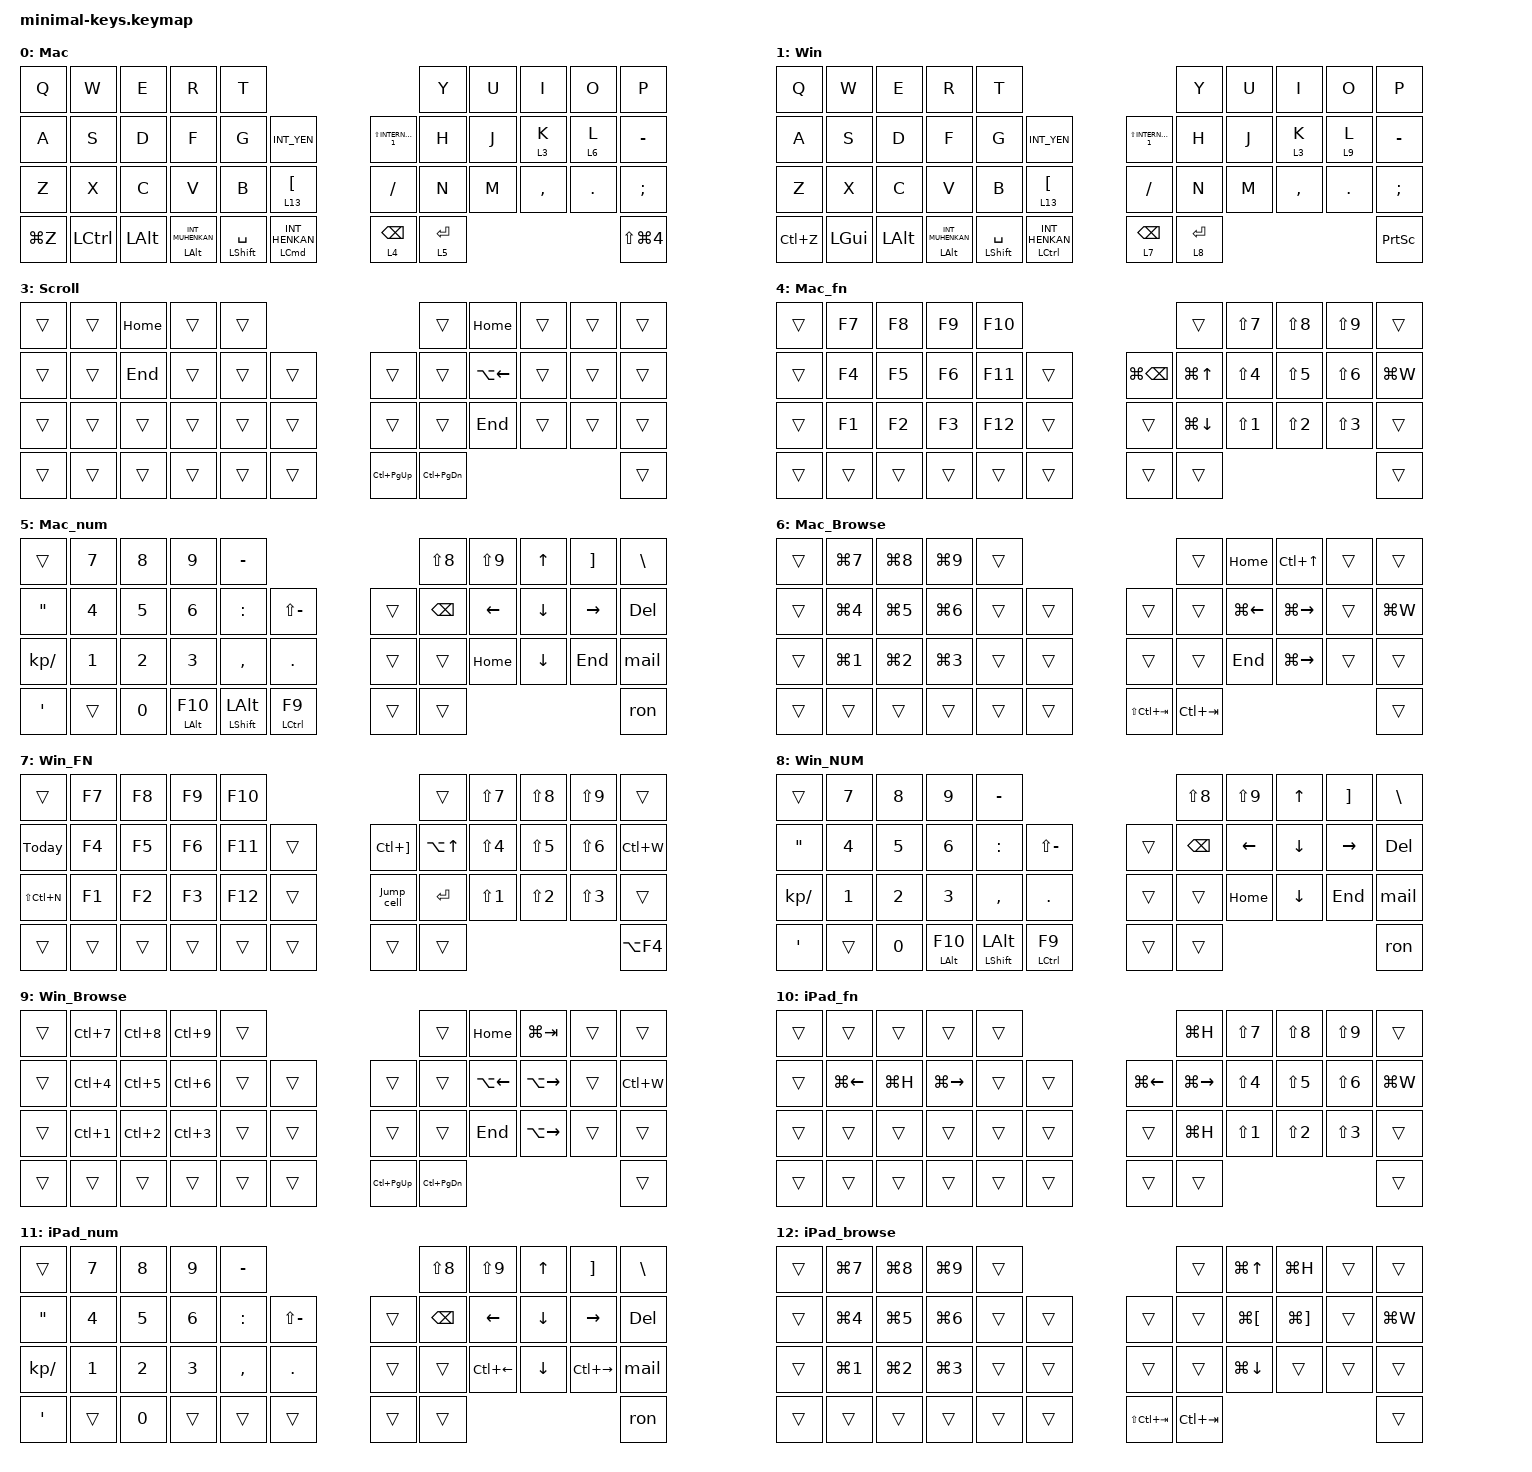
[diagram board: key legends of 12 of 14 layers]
#include <behaviors.dtsi>
#include <dt-bindings/zmk/bt.h>
#include <dt-bindings/zmk/keys.h>
#include <dt-bindings/zmk/pointing.h>

#undef ZMK_POINTING_DEFAULT_SCRL_VAL

#define ZMK_POINTING_DEFAULT_SCRL_VAL 100
#define MOUSE 6

&mt {
    flavor = "balanced";
    quick-tap-ms = <0>;
};

/ {
    combos {
        compatible = "zmk,combos";

        tab {
            bindings = <&kp TAB>;
            key-positions = <23 22>;
        };

        eq {
            bindings = <&kp LS(MINUS)>;
            key-positions = <20 21>;
        };

        question {
            bindings = <&kp QUESTION>;
            key-positions = <32 33>;
        };

        L_click {
            bindings = <&mkp LCLK>;
            key-positions = <18 19>;
        };

        R_click {
            bindings = <&mkp RCLK>;
            key-positions = <19 20>;
        };

        Escape {
            bindings = <&kp ESCAPE>;
            key-positions = <1 2>;
        };

        Mac_copy {
            bindings = <&kp LG(C)>;
            key-positions = <24 26>;
            layers = <0 5 7 6 2 10 11 12>;
        };

        Mac_Paste {
            bindings = <&kp LG(V)>;
            key-positions = <24 25>;
            layers = <0 5 7 6 10 11 2 12>;
        };

        Mac_Cut {
            bindings = <&kp LG(X)>;
            key-positions = <23 24>;
            layers = <0 5 6 2 4 10 11 12>;
        };

        L_click2 {
            bindings = <&mkp LCLK>;
            key-positions = <30 31>;
        };

        R_click2 {
            bindings = <&mkp RCLK>;
            key-positions = <31 32>;
        };

        Win_copy {
            bindings = <&kp LC(C)>;
            key-positions = <24 26>;
            layers = <1 7 8 9>;
        };

        Win_Cut {
            bindings = <&kp LC(X)>;
            key-positions = <24 23>;
            layers = <1 7 8 9>;
        };

        Win_Paste {
            bindings = <&kp LC(V)>;
            key-positions = <24 25>;
            layers = <1 8 7 9>;
        };
    };

    macros {
        to_layer_0: to_layer_0 {
            compatible = "zmk,behavior-macro-one-param";
            #binding-cells = <1>;
            bindings = <&to 0 &macro_param_1to1 &kp MACRO_PLACEHOLDER>;
            label = "TO_LAYER_0";
        };

        Jump_cell: Jump_cell {
            compatible = "zmk,behavior-macro";
            #binding-cells = <0>;
            bindings = <&kp F5>, <&macro_wait_time 20>, <&kp ENTER>;

            label = "JUMP_CELL";
        };

        Today: Today {
            compatible = "zmk,behavior-macro";
            #binding-cells = <0>;
            bindings =
                <&kp LS(LC(D))>,
                <&macro_wait_time 20>,
                <&kp LEFT_SHIFT &kp LCTRL>,
                <&macro_wait_time 20>,
                <&kp LEFT_SHIFT &kp LCTRL>,
                <&macro_wait_time 30>;

            label = "TODAY";
        };

        sw_Mac: sw_Mac {
            compatible = "zmk,behavior-macro";
            #binding-cells = <0>;
            bindings =
                <&bt BT_SEL 0>,
                <&macro_wait_time 500>,
                <&tog_off 1>,
                <&macro_wait_time 200>,
                <&tog_off 2>,
                <&macro_wait_time 200>;

            label = "SW_MAC";
        };

        sw_Win: sw_Win {
            compatible = "zmk,behavior-macro";
            #binding-cells = <0>;
            bindings =
                <&bt BT_SEL 1>,
                <&macro_wait_time 500>,
                <&tog_off 1>,
                <&macro_wait_time 200>,
                <&tog_off 2>,
                <&macro_wait_time 200>,
                <&tog_on 1>;

            label = "SW_WIN";
        };

        sw_iPad: sw_iPad {
            compatible = "zmk,behavior-macro";
            #binding-cells = <0>;
            bindings =
                <&bt BT_SEL 2>,
                <&macro_wait_time 500>,
                <&tog_off 1>,
                <&macro_wait_time 200>,
                <&tog_off 2>,
                <&macro_wait_time 200>,
                <&tog_on 2>;

            label = "SW_IPAD";
        };

        ron: ron {
            compatible = "zmk,behavior-macro";
            #binding-cells = <0>;
            bindings = <&kp R &kp O &kp N &kp B &kp A &kp K &kp U &kp R &kp O &kp N &kp B &kp A &kp K &kp U &kp N2 &kp N6 &kp LEFT_BRACKET &kp RET>;
            label = "RON";
        };

        mail: mail {
            compatible = "zmk,behavior-macro";
            #binding-cells = <0>;
            bindings = <&kp Y &kp U &kp K &kp I &kp DOT &kp M &kp O &kp R &kp I &kp T &kp A &kp N &kp I &kp LEFT_BRACKET &kp P &kp W &kp C &kp DOT &kp C &kp O &kp M &kp TAB>;
            label = "MAIL";
            wait-ms = <20>;
        };
    };

    behaviors {
        lt_to_layer_0: lt_to_layer_0 {
            compatible = "zmk,behavior-hold-tap";
            label = "LAYER_TAP_TO_0";
            bindings = <&mo>, <&to_layer_0>;

            #binding-cells = <2>;
            tapping-term-ms = <200>;
        };

        scroll_up_down: behavior_sensor_rotate_mouse_wheel_up_down {
            compatible = "zmk,behavior-sensor-rotate";
            #sensor-binding-cells = <0>;
            bindings = <&msc SCRL_UP>, <&msc SCRL_DOWN>;

            tap-ms = <20>;
        };

        scroll: scroll {
            compatible = "zmk,behavior-sensor-rotate";
            label = "SCROLL";
            #sensor-binding-cells = <0>;
            bindings = <&msc SCRL_DOWN>, <&msc SCRL_UP>;
        };

        tog_on: toggle_layer_on_only {
            compatible = "zmk,behavior-toggle-layer";
            #binding-cells = <1>;
        };

        tog_off: toggle_layer_off_only {
            compatible = "zmk,behavior-toggle-layer";
            #binding-cells = <1>;
            toggle-mode = "off";
        };
    };

    keymap {
        compatible = "zmk,keymap";

        Mac {
            bindings = <
&kp Q      &kp W      &kp E         &kp R                      &kp T                                                                         &kp Y        &kp U  &kp I      &kp O    &kp P
&kp A      &kp S      &kp D         &kp F                      &kp G                 &kp INT_YEN                    &kp LS(INTERNATIONAL_1)  &kp H        &kp J  &lt 3 K    &lt 6 L  &kp MINUS
&kp Z      &kp X      &kp C         &kp V                      &kp B                 &lt 13 LEFT_BRACKET            &kp SLASH                &kp N        &kp M  &kp COMMA  &kp DOT  &kp SEMICOLON
&kp LG(Z)  &kp LCTRL  &kp LEFT_ALT  &mt LEFT_ALT INT_MUHENKAN  &mt LEFT_SHIFT SPACE  &mt LEFT_COMMAND INT_HENKAN    &lt 4 BACKSPACE          &lt 5 ENTER                             &kp LS(LG(NUMBER_4))
            >;

            sensor-bindings = <&scroll_up_down>;
        };

        Win {
            bindings = <
&kp Q      &kp W         &kp E         &kp R                      &kp T                                                                  &kp Y        &kp U  &kp I      &kp O    &kp P
&kp A      &kp S         &kp D         &kp F                      &kp G                 &kp INT_YEN             &kp LS(INTERNATIONAL_1)  &kp H        &kp J  &lt 3 K    &lt 9 L  &kp MINUS
&kp Z      &kp X         &kp C         &kp V                      &kp B                 &lt 13 LEFT_BRACKET     &kp SLASH                &kp N        &kp M  &kp COMMA  &kp DOT  &kp SEMICOLON
&kp LC(Z)  &kp LEFT_GUI  &kp LEFT_ALT  &mt LEFT_ALT INT_MUHENKAN  &mt LEFT_SHIFT SPACE  &mt LCTRL INT_HENKAN    &lt 7 BACKSPACE          &lt 8 ENTER                             &kp PRINTSCREEN
            >;

            sensor-bindings = <&scroll_up_down>;
        };

        iPad {
            bindings = <
&kp Q      &kp W                                 &kp E         &kp R                  &kp T                                                                 &kp Y         &kp U  &kp I      &kp O     &kp P
&kp A      &kp S                                 &kp D         &kp F                  &kp G                 &kp INTERNATIONAL_3    &kp LS(INTERNATIONAL_1)  &kp H         &kp J  &lt 3 K    &lt 12 L  &kp MINUS
&kp Z      &kp X                                 &kp C         &kp V                  &kp B                 &lt 13 LEFT_BRACKET    &kp SLASH                &kp N         &kp M  &kp COMMA  &kp DOT   &kp SEMICOLON
&kp LG(Z)  &kp C_AC_NEXT_KEYBOARD_LAYOUT_SELECT  &kp LEFT_ALT  &mt (LCTRL) LC(SPACE)  &mt LEFT_SHIFT SPACE  &kp LEFT_COMMAND       &lt 10 BACKSPACE         &lt 11 ENTER                              &kp LS(LG(NUMBER_4))
            >;

            sensor-bindings = <&scroll_up_down>;
        };

        Scroll {
            bindings = <
&trans  &trans  &kp HOME  &trans  &trans                             &trans             &kp HOME            &trans  &trans  &trans
&trans  &trans  &kp END   &trans  &trans  &trans    &trans           &trans             &kp LA(LEFT_ARROW)  &trans  &trans  &trans
&trans  &trans  &trans    &trans  &trans  &trans    &trans           &trans             &kp END             &trans  &trans  &trans
&trans  &trans  &trans    &trans  &trans  &trans    &kp LC(PAGE_UP)  &kp LC(PAGE_DOWN)                                      &trans
            >;

            sensor-bindings = <&scroll_up_down>;
        };

        Mac_fn {
            bindings = <
&trans  &kp F7  &kp F8  &kp F9  &kp F10                               &trans              &kp LS(N7)  &kp LS(N8)  &kp LS(N9)  &trans
&trans  &kp F4  &kp F5  &kp F6  &kp F11  &trans    &kp LG(BACKSPACE)  &kp LG(UP_ARROW)    &kp LS(N4)  &kp LS(N5)  &kp LS(N6)  &kp LG(W)
&trans  &kp F1  &kp F2  &kp F3  &kp F12  &trans    &trans             &kp LG(DOWN_ARROW)  &kp LS(N1)  &kp LS(N2)  &kp LS(N3)  &trans
&trans  &trans  &trans  &trans  &trans   &trans    &trans             &trans                                                  &trans
            >;

            sensor-bindings = <&inc_dec_kp C_VOLUME_DOWN C_VOLUME_UP>;
        };

        Mac_num {
            bindings = <
&trans             &kp N7  &kp N8        &kp N9            &kp MINUS                                         &kp LS(NUMBER_8)  &kp LS(NUMBER_9)  &kp UP_ARROW    &kp RIGHT_BRACKET  &kp BACKSLASH
&kp DOUBLE_QUOTES  &kp N4  &kp N5        &kp N6            &kp COLON                &kp LS(MINUS)    &trans  &kp BACKSPACE     &kp LEFT_ARROW    &kp DOWN_ARROW  &kp RIGHT_ARROW    &kp DELETE
&kp KP_SLASH       &kp N1  &kp N2        &kp N3            &kp COMMA                &kp PERIOD       &trans  &trans            &kp HOME          &kp DOWN_ARROW  &kp END            &mail
&kp SINGLE_QUOTE   &trans  &kp NUMBER_0  &mt LEFT_ALT F10  &mt LEFT_SHIFT LEFT_ALT  &mt LCTRL F9     &trans  &trans                                                                 &ron
            >;

            sensor-bindings = <&scroll_up_down>;
        };

        Mac_Browse {
            bindings = <
&trans  &kp LG(N7)  &kp LG(N8)  &kp LG(N9)  &trans                             &trans       &kp HOME            &kp LC(UP_ARROW)     &trans  &trans
&trans  &kp LG(N4)  &kp LG(N5)  &kp LG(N6)  &trans  &trans    &trans           &trans       &kp LG(LEFT_ARROW)  &kp LG(RIGHT_ARROW)  &trans  &kp LG(W)
&trans  &kp LG(N1)  &kp LG(N2)  &kp LG(N3)  &trans  &trans    &trans           &trans       &kp END             &kp LG(RIGHT_ARROW)  &trans  &trans
&trans  &trans      &trans      &trans      &trans  &trans    &kp LS(LC(TAB))  &kp LC(TAB)                                                   &trans
            >;

            sensor-bindings = <&scroll_up_down>;
        };

        Win_FN {
            bindings = <
&trans         &kp F7  &kp F8  &kp F9  &kp F10                                   &trans            &kp LS(N7)  &kp LS(N8)  &kp LS(N9)  &trans
&Today         &kp F4  &kp F5  &kp F6  &kp F11  &trans    &kp LC(RIGHT_BRACKET)  &kp LA(UP_ARROW)  &kp LS(N4)  &kp LS(N5)  &kp LS(N6)  &kp LC(W)
&kp LS(LC(N))  &kp F1  &kp F2  &kp F3  &kp F12  &trans    &Jump_cell             &kp ENTER         &kp LS(N1)  &kp LS(N2)  &kp LS(N3)  &trans
&trans         &trans  &trans  &trans  &trans   &trans    &trans                 &trans                                                &kp LA(F4)
            >;

            sensor-bindings = <&inc_dec_kp C_VOLUME_DOWN C_VOLUME_UP>;
        };

        Win_NUM {
            bindings = <
&trans             &kp N7  &kp N8        &kp N9            &kp MINUS                                         &kp LS(NUMBER_8)  &kp LS(NUMBER_9)  &kp UP_ARROW    &kp RIGHT_BRACKET  &kp BACKSLASH
&kp DOUBLE_QUOTES  &kp N4  &kp N5        &kp N6            &kp COLON                &kp LS(MINUS)    &trans  &kp BACKSPACE     &kp LEFT_ARROW    &kp DOWN_ARROW  &kp RIGHT_ARROW    &kp DELETE
&kp KP_SLASH       &kp N1  &kp N2        &kp N3            &kp COMMA                &kp PERIOD       &trans  &trans            &kp HOME          &kp DOWN_ARROW  &kp END            &mail
&kp SINGLE_QUOTE   &trans  &kp NUMBER_0  &mt LEFT_ALT F10  &mt LEFT_SHIFT LEFT_ALT  &mt LCTRL F9     &trans  &trans                                                                 &ron
            >;

            sensor-bindings = <&scroll_up_down>;
        };

        Win_Browse {
            bindings = <
&trans  &kp LC(N7)        &kp LC(N8)  &kp LC(N9)  &trans                             &trans             &kp HOME            &kp LG(TAB)          &trans  &trans
&trans  &kp LC(N4)        &kp LC(N5)  &kp LC(N6)  &trans  &trans    &trans           &trans             &kp LA(LEFT_ARROW)  &kp LA(RIGHT_ARROW)  &trans  &kp LC(W)
&trans  &kp LC(NUMBER_1)  &kp LC(N2)  &kp LC(N3)  &trans  &trans    &trans           &trans             &kp END             &kp LA(RIGHT_ARROW)  &trans  &trans
&trans  &trans            &trans      &trans      &trans  &trans    &kp LC(PAGE_UP)  &kp LC(PAGE_DOWN)                                                   &trans
            >;

            sensor-bindings = <&scroll_up_down>;
        };

        iPad_fn {
            bindings = <
&trans  &trans              &trans     &trans               &trans                                &kp LG(H)            &kp LS(N7)  &kp LS(N8)  &kp LS(N9)  &trans
&trans  &kp LG(LEFT_ARROW)  &kp LG(H)  &kp LG(RIGHT_ARROW)  &trans  &trans    &kp LG(LEFT_ARROW)  &kp LG(RIGHT_ARROW)  &kp LS(N4)  &kp LS(N5)  &kp LS(N6)  &kp LG(W)
&trans  &trans              &trans     &trans               &trans  &trans    &trans              &kp LG(H)            &kp LS(N1)  &kp LS(N2)  &kp LS(N3)  &trans
&trans  &trans              &trans     &trans               &trans  &trans    &trans              &trans                                                   &trans
            >;

            sensor-bindings = <&inc_dec_kp C_VOLUME_DOWN C_VOLUME_UP>;
        };

        iPad_num {
            bindings = <
&trans             &kp N7  &kp N8        &kp N9  &kp MINUS                           &kp LS(NUMBER_8)  &kp LS(NUMBER_9)    &kp UP_ARROW    &kp RIGHT_BRACKET    &kp BACKSLASH
&kp DOUBLE_QUOTES  &kp N4  &kp N5        &kp N6  &kp COLON  &kp LS(MINUS)    &trans  &kp BACKSPACE     &kp LEFT_ARROW      &kp DOWN_ARROW  &kp RIGHT_ARROW      &kp DELETE
&kp KP_SLASH       &kp N1  &kp N2        &kp N3  &kp COMMA  &kp PERIOD       &trans  &trans            &kp LC(LEFT_ARROW)  &kp DOWN_ARROW  &kp LC(RIGHT_ARROW)  &mail
&kp SINGLE_QUOTE   &trans  &kp NUMBER_0  &trans  &trans     &trans           &trans  &trans                                                                     &ron
            >;

            sensor-bindings = <&scroll_up_down>;
        };

        iPad_browse {
            bindings = <
&trans  &kp LG(N7)  &kp LG(N8)  &kp LG(N9)  &trans                             &trans       &kp LG(UP_ARROW)      &kp LG(H)              &trans  &trans
&trans  &kp LG(N4)  &kp LG(N5)  &kp LG(N6)  &trans  &trans    &trans           &trans       &kp LG(LEFT_BRACKET)  &kp LG(RIGHT_BRACKET)  &trans  &kp LG(W)
&trans  &kp LG(N1)  &kp LG(N2)  &kp LG(N3)  &trans  &trans    &trans           &trans       &kp LG(DOWN_ARROW)    &trans                 &trans  &trans
&trans  &trans      &trans      &trans      &trans  &trans    &kp LS(LC(TAB))  &kp LC(TAB)                                                       &trans
            >;

            sensor-bindings = <&scroll_up_down>;
        };

        Bluetooth {
            bindings = <
&trans  &trans          &kp UP_ARROW    &trans           &trans                    &trans  &trans   &trans   &trans    &trans
&trans  &kp LEFT_ARROW  &kp DOWN_ARROW  &kp RIGHT_ARROW  &trans  &trans    &trans  &trans  &sw_Mac  &sw_Win  &sw_iPad  &trans
&trans  &trans          &trans          &trans           &trans  &trans    &trans  &trans  &trans   &trans   &trans    &bt BT_CLR_ALL
&trans  &trans          &trans          &trans           &trans  &trans    &trans  &trans                              &bt BT_CLR
            >;
        };
    };
};
